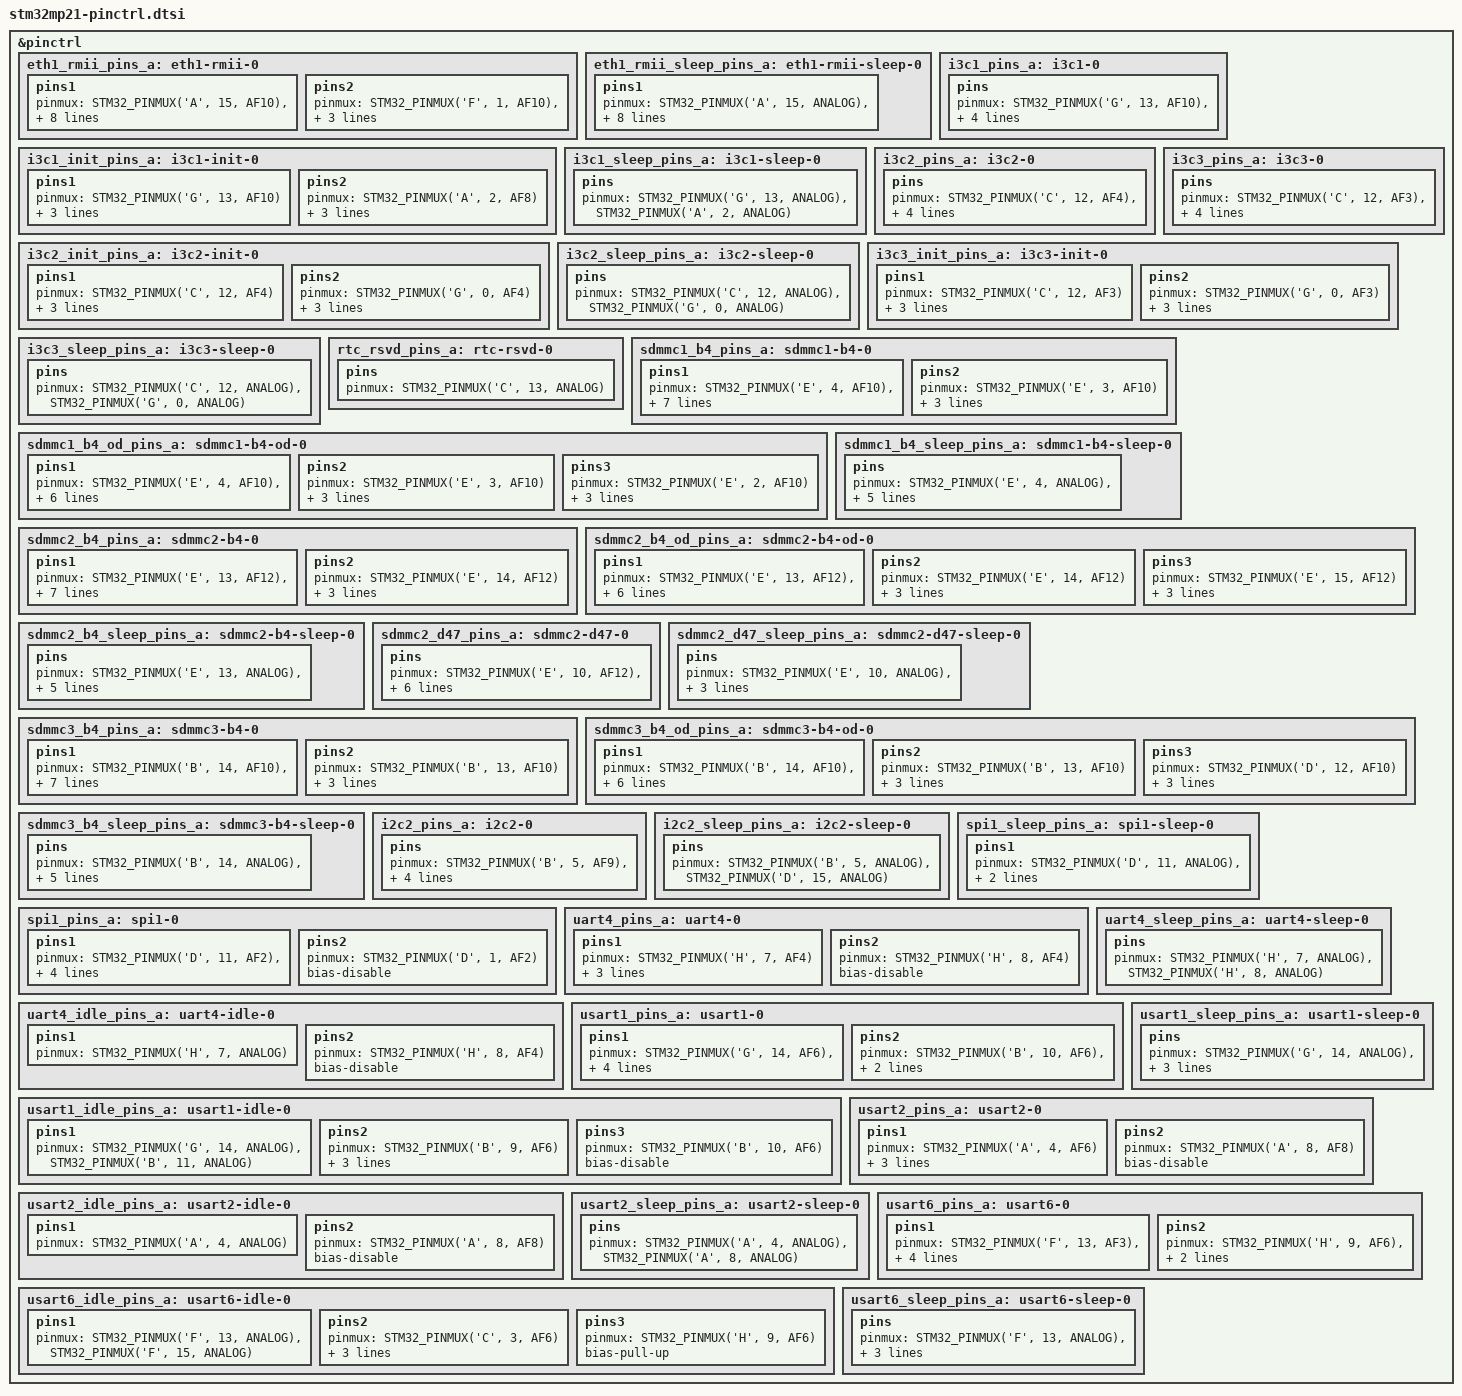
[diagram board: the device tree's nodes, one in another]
// SPDX-License-Identifier: (GPL-2.0-only OR BSD-3-Clause)
/*
 * Copyright (C) 2024-2025, STMicroelectronics - All Rights Reserved
 * Author: Amelie Delaunay <amelie.delaunay@foss.st.com> for STMicroelectronics.
 */
#include <dt-bindings/pinctrl/stm32-pinfunc.h>

&pinctrl {
	/omit-if-no-ref/
	eth1_rmii_pins_a: eth1-rmii-0 {
		pins1 {
			pinmux = <STM32_PINMUX('A', 15, AF10)>, /* ETH_RMII_TXD0 */
				 <STM32_PINMUX('C', 1, AF10)>, /* ETH_RMII_TXD1 */
				 <STM32_PINMUX('A', 13, AF10)>, /* ETH_RMII_TX_EN */
				 <STM32_PINMUX('F', 8, AF9)>, /* ETH_RMII_ETHCK */
				 <STM32_PINMUX('F', 2, AF10)>, /* ETH_MDIO */
				 <STM32_PINMUX('F', 0, AF10)>; /* ETH_MDC */
			bias-disable;
			drive-push-pull;
			slew-rate = <1>;
		};

		pins2 {
			pinmux = <STM32_PINMUX('F', 1, AF10)>, /* ETH_RMII_RXD0 */
				 <STM32_PINMUX('C', 2, AF10)>, /* ETH_RMII_RXD1 */
				 <STM32_PINMUX('A', 11, AF10)>; /* ETH_RMII_CRS_DV */
			bias-disable;
		};

	};

	/omit-if-no-ref/
	eth1_rmii_sleep_pins_a: eth1-rmii-sleep-0 {
		pins1 {
			pinmux = <STM32_PINMUX('A', 15, ANALOG)>, /* ETH_RMII_TXD0 */
				 <STM32_PINMUX('C', 1, ANALOG)>, /* ETH_RMII_TXD1 */
				 <STM32_PINMUX('A', 13, ANALOG)>, /* ETH_RMII_TX_EN */
				 <STM32_PINMUX('F', 8, ANALOG)>, /* ETH_RMII_ETHCK */
				 <STM32_PINMUX('F', 2, ANALOG)>, /* ETH_MDIO */
				 <STM32_PINMUX('F', 0, ANALOG)>, /* ETH_MDC */
				 <STM32_PINMUX('F', 1, ANALOG)>, /* ETH_RMII_RXD0 */
				 <STM32_PINMUX('C', 2, ANALOG)>, /* ETH_RMII_RXD1 */
				 <STM32_PINMUX('A', 11, ANALOG)>; /* ETH_RMII_CRS_DV */
		};
	};

	/omit-if-no-ref/
	i3c1_pins_a: i3c1-0 {
		pins {
			pinmux = <STM32_PINMUX('G', 13, AF10)>, /* I3C1_SCL */
				 <STM32_PINMUX('A', 2, AF8)>; /* I3C1_SDA */
			drive-push-pull;
			bias-disable;
			slew-rate = <3>;
		};
	};

	/omit-if-no-ref/
	i3c1_init_pins_a: i3c1-init-0 {
		pins1 {
			pinmux = <STM32_PINMUX('G', 13, AF10)>; /* I3C1_SCL */
			drive-push-pull;
			bias-disable;
			slew-rate = <1>;
		};
		pins2 {
			pinmux = <STM32_PINMUX('A', 2, AF8)>; /* I3C1_SDA */
			drive-push-pull;
			bias-pull-up;
			slew-rate = <1>;
		};
	};

	/omit-if-no-ref/
	i3c1_sleep_pins_a: i3c1-sleep-0 {
		pins {
			pinmux = <STM32_PINMUX('G', 13, ANALOG)>, /* I3C1_SCL */
				 <STM32_PINMUX('A', 2, ANALOG)>; /* I3C1_SDA */
		};
	};

	/omit-if-no-ref/
	i3c2_pins_a: i3c2-0 {
		pins {
			pinmux = <STM32_PINMUX('C', 12, AF4)>, /* I3C2_SCL */
				 <STM32_PINMUX('G', 0, AF4)>; /* I3C2_SDA */
			drive-push-pull;
			bias-disable;
			slew-rate = <3>;
		};
	};

	/omit-if-no-ref/
	i3c2_init_pins_a: i3c2-init-0 {
		pins1 {
			pinmux = <STM32_PINMUX('C', 12, AF4)>; /* I3C2_SCL */
			drive-push-pull;
			bias-disable;
			slew-rate = <3>;
		};
		pins2 {
			pinmux = <STM32_PINMUX('G', 0, AF4)>; /* I3C2_SDA */
			drive-push-pull;
			bias-pull-up;
			slew-rate = <3>;
		};
	};

	/omit-if-no-ref/
	i3c2_sleep_pins_a: i3c2-sleep-0 {
		pins {
			pinmux = <STM32_PINMUX('C', 12, ANALOG)>, /* I3C2_SCL */
				 <STM32_PINMUX('G', 0, ANALOG)>; /* I3C2_SDA */
		};
	};

	/omit-if-no-ref/
	i3c3_pins_a: i3c3-0 {
		pins {
			pinmux = <STM32_PINMUX('C', 12, AF3)>, /* I3C3_SCL */
				 <STM32_PINMUX('G', 0, AF3)>; /* I3C3_SDA */
			drive-push-pull;
			bias-disable;
			slew-rate = <3>;
		};
	};

	/omit-if-no-ref/
	i3c3_init_pins_a: i3c3-init-0 {
		pins1 {
			pinmux = <STM32_PINMUX('C', 12, AF3)>; /* I3C3_SCL */
			drive-push-pull;
			bias-disable;
			slew-rate = <3>;
		};
		pins2 {
			pinmux = <STM32_PINMUX('G', 0, AF3)>; /* I3C3_SDA */
			drive-push-pull;
			bias-pull-up;
			slew-rate = <3>;
		};
	};

	/omit-if-no-ref/
	i3c3_sleep_pins_a: i3c3-sleep-0 {
		pins {
			pinmux = <STM32_PINMUX('C', 12, ANALOG)>, /* I3C3_SCL */
				 <STM32_PINMUX('G', 0, ANALOG)>; /* I3C3_SDA */
		};
	};

	/omit-if-no-ref/
	rtc_rsvd_pins_a: rtc-rsvd-0 {
		pins {
			pinmux = <STM32_PINMUX('C', 13, ANALOG)>; /* RTC_OUT1 */
		};
	};

	/omit-if-no-ref/
	sdmmc1_b4_pins_a: sdmmc1-b4-0 {
		pins1 {
			pinmux = <STM32_PINMUX('E', 4, AF10)>, /* SDMMC1_D0 */
				 <STM32_PINMUX('E', 5, AF10)>, /* SDMMC1_D1 */
				 <STM32_PINMUX('E', 0, AF10)>, /* SDMMC1_D2 */
				 <STM32_PINMUX('E', 1, AF10)>, /* SDMMC1_D3 */
				 <STM32_PINMUX('E', 2, AF10)>; /* SDMMC1_CMD */
			slew-rate = <2>;
			drive-push-pull;
			bias-disable;
		};
		pins2 {
			pinmux = <STM32_PINMUX('E', 3, AF10)>; /* SDMMC1_CK */
			slew-rate = <3>;
			drive-push-pull;
			bias-disable;
		};
	};

	/omit-if-no-ref/
	sdmmc1_b4_od_pins_a: sdmmc1-b4-od-0 {
		pins1 {
			pinmux = <STM32_PINMUX('E', 4, AF10)>, /* SDMMC1_D0 */
				 <STM32_PINMUX('E', 5, AF10)>, /* SDMMC1_D1 */
				 <STM32_PINMUX('E', 0, AF10)>, /* SDMMC1_D2 */
				 <STM32_PINMUX('E', 1, AF10)>; /* SDMMC1_D3 */
			slew-rate = <2>;
			drive-push-pull;
			bias-disable;
		};
		pins2 {
			pinmux = <STM32_PINMUX('E', 3, AF10)>; /* SDMMC1_CK */
			slew-rate = <3>;
			drive-push-pull;
			bias-disable;
		};
		pins3 {
			pinmux = <STM32_PINMUX('E', 2, AF10)>; /* SDMMC1_CMD */
			slew-rate = <2>;
			drive-open-drain;
			bias-disable;
		};
	};

	/omit-if-no-ref/
	sdmmc1_b4_sleep_pins_a: sdmmc1-b4-sleep-0 {
		pins {
			pinmux = <STM32_PINMUX('E', 4, ANALOG)>, /* SDMMC1_D0 */
				 <STM32_PINMUX('E', 5, ANALOG)>, /* SDMMC1_D1 */
				 <STM32_PINMUX('E', 0, ANALOG)>, /* SDMMC1_D2 */
				 <STM32_PINMUX('E', 1, ANALOG)>, /* SDMMC1_D3 */
				 <STM32_PINMUX('E', 3, ANALOG)>, /* SDMMC1_CK */
				 <STM32_PINMUX('E', 2, ANALOG)>; /* SDMMC1_CMD */
		};
	};

	/omit-if-no-ref/
	sdmmc2_b4_pins_a: sdmmc2-b4-0 {
		pins1 {
			pinmux = <STM32_PINMUX('E', 13, AF12)>, /* SDMMC2_D0 */
				 <STM32_PINMUX('E', 11, AF12)>, /* SDMMC2_D1 */
				 <STM32_PINMUX('E', 8, AF12)>, /* SDMMC2_D2 */
				 <STM32_PINMUX('E', 12, AF12)>, /* SDMMC2_D3 */
				 <STM32_PINMUX('E', 15, AF12)>; /* SDMMC2_CMD */
			slew-rate = <2>;
			drive-push-pull;
			bias-pull-up;
		};
		pins2 {
			pinmux = <STM32_PINMUX('E', 14, AF12)>; /* SDMMC2_CK */
			slew-rate = <3>;
			drive-push-pull;
			bias-pull-up;
		};
	};

	/omit-if-no-ref/
	sdmmc2_b4_od_pins_a: sdmmc2-b4-od-0 {
		pins1 {
			pinmux = <STM32_PINMUX('E', 13, AF12)>, /* SDMMC2_D0 */
				 <STM32_PINMUX('E', 11, AF12)>, /* SDMMC2_D1 */
				 <STM32_PINMUX('E', 8, AF12)>, /* SDMMC2_D2 */
				 <STM32_PINMUX('E', 12, AF12)>; /* SDMMC2_D3 */
			slew-rate = <2>;
			drive-push-pull;
			bias-pull-up;
		};
		pins2 {
			pinmux = <STM32_PINMUX('E', 14, AF12)>; /* SDMMC2_CK */
			slew-rate = <3>;
			drive-push-pull;
			bias-pull-up;
		};
		pins3 {
			pinmux = <STM32_PINMUX('E', 15, AF12)>; /* SDMMC2_CMD */
			slew-rate = <2>;
			drive-open-drain;
			bias-pull-up;
		};
	};

	/omit-if-no-ref/
	sdmmc2_b4_sleep_pins_a: sdmmc2-b4-sleep-0 {
		pins {
			pinmux = <STM32_PINMUX('E', 13, ANALOG)>, /* SDMMC2_D0 */
				 <STM32_PINMUX('E', 11, ANALOG)>, /* SDMMC2_D1 */
				 <STM32_PINMUX('E', 8, ANALOG)>, /* SDMMC2_D2 */
				 <STM32_PINMUX('E', 12, ANALOG)>, /* SDMMC2_D3 */
				 <STM32_PINMUX('E', 14, ANALOG)>, /* SDMMC2_CK */
				 <STM32_PINMUX('E', 15, ANALOG)>; /* SDMMC2_CMD */
		};
	};

	/omit-if-no-ref/
	sdmmc2_d47_pins_a: sdmmc2-d47-0 {
		pins {
			pinmux = <STM32_PINMUX('E', 10, AF12)>, /* SDMMC2_D4 */
				 <STM32_PINMUX('E', 9, AF12)>, /* SDMMC2_D5 */
				 <STM32_PINMUX('E', 6, AF12)>, /* SDMMC2_D6 */
				 <STM32_PINMUX('E', 7, AF12)>; /* SDMMC2_D7 */
			slew-rate = <2>;
			drive-push-pull;
			bias-pull-up;
		};
	};

	/omit-if-no-ref/
	sdmmc2_d47_sleep_pins_a: sdmmc2-d47-sleep-0 {
		pins {
			pinmux = <STM32_PINMUX('E', 10, ANALOG)>, /* SDMMC2_D4 */
				 <STM32_PINMUX('E', 9, ANALOG)>, /* SDMMC2_D5 */
				 <STM32_PINMUX('E', 6, ANALOG)>, /* SDMMC2_D6 */
				 <STM32_PINMUX('E', 7, ANALOG)>; /* SDMMC2_D7 */
		};
	};

	/omit-if-no-ref/
	sdmmc3_b4_pins_a: sdmmc3-b4-0 {
		pins1 {
			pinmux = <STM32_PINMUX('B', 14, AF10)>, /* SDMMC3_D0 */
				 <STM32_PINMUX('D', 13, AF10)>, /* SDMMC3_D1 */
				 <STM32_PINMUX('B', 12, AF10)>, /* SDMMC3_D2 */
				 <STM32_PINMUX('D', 14, AF12)>, /* SDMMC3_D3 */
				 <STM32_PINMUX('D', 12, AF10)>; /* SDMMC3_CMD */
			slew-rate = <2>;
			drive-push-pull;
			bias-pull-up;
		};
		pins2 {
			pinmux = <STM32_PINMUX('B', 13, AF10)>; /* SDMMC3_CK */
			slew-rate = <3>;
			drive-push-pull;
			bias-pull-up;
		};
	};

	/omit-if-no-ref/
	sdmmc3_b4_od_pins_a: sdmmc3-b4-od-0 {
		pins1 {
			pinmux = <STM32_PINMUX('B', 14, AF10)>, /* SDMMC3_D0 */
				 <STM32_PINMUX('D', 13, AF10)>, /* SDMMC3_D1 */
				 <STM32_PINMUX('B', 12, AF10)>, /* SDMMC3_D2 */
				 <STM32_PINMUX('D', 14, AF12)>; /* SDMMC3_D3 */
			slew-rate = <2>;
			drive-push-pull;
			bias-pull-up;
		};
		pins2 {
			pinmux = <STM32_PINMUX('B', 13, AF10)>; /* SDMMC3_CK */
			slew-rate = <3>;
			drive-push-pull;
			bias-pull-up;
		};
		pins3 {
			pinmux = <STM32_PINMUX('D', 12, AF10)>; /* SDMMC3_CMD */
			slew-rate = <2>;
			drive-open-drain;
			bias-pull-up;
		};
	};

	/omit-if-no-ref/
	sdmmc3_b4_sleep_pins_a: sdmmc3-b4-sleep-0 {
		pins {
			pinmux = <STM32_PINMUX('B', 14, ANALOG)>, /* SDMMC1_D0 */
				 <STM32_PINMUX('D', 13, ANALOG)>, /* SDMMC1_D1 */
				 <STM32_PINMUX('B', 12, ANALOG)>, /* SDMMC1_D2 */
				 <STM32_PINMUX('D', 14, ANALOG)>, /* SDMMC1_D3 */
				 <STM32_PINMUX('B', 13, ANALOG)>, /* SDMMC1_CK */
				 <STM32_PINMUX('D', 12, ANALOG)>; /* SDMMC1_CMD */
		};
	};

	/omit-if-no-ref/
	i2c2_pins_a: i2c2-0 {
		pins {
			pinmux = <STM32_PINMUX('B', 5, AF9)>, /* I2C2_SCL */
				 <STM32_PINMUX('D', 15, AF6)>; /* I2C2_SDA */
			bias-disable;
			drive-open-drain;
			slew-rate = <0>;
		};
	};

	/omit-if-no-ref/
	i2c2_sleep_pins_a: i2c2-sleep-0 {
		pins {
			pinmux = <STM32_PINMUX('B', 5, ANALOG)>, /* I2C2_SCL */
				 <STM32_PINMUX('D', 15, ANALOG)>; /* I2C2_SDA */
		};
	};

	/omit-if-no-ref/
	spi1_pins_a: spi1-0 {
		pins1 {
			pinmux = <STM32_PINMUX('D', 11, AF2)>, /* SPI1_SCK */
				 <STM32_PINMUX('I', 5, AF3)>; /* SPI1_MOSI */
			drive-push-pull;
			bias-disable;
			slew-rate = <1>;
		};
		pins2 {
			pinmux = <STM32_PINMUX('D', 1, AF2)>; /* SPI1_MISO */
			bias-disable;
		};
	};

	/omit-if-no-ref/
	spi1_sleep_pins_a: spi1-sleep-0 {
		pins1 {
			pinmux = <STM32_PINMUX('D', 11, ANALOG)>, /* SPI1_SCK */
				 <STM32_PINMUX('I', 5, ANALOG)>, /* SPI1_MOSI */
				 <STM32_PINMUX('D', 1, ANALOG)>; /* SPI1_MISO */
		};
	};

	/omit-if-no-ref/
	uart4_pins_a: uart4-0 {
		pins1 {
			pinmux = <STM32_PINMUX('H', 7, AF4)>; /* UART4_TX */
			bias-disable;
			drive-push-pull;
			slew-rate = <0>;
		};
		pins2 {
			pinmux = <STM32_PINMUX('H', 8, AF4)>; /* UART4_RX */
			bias-disable;
		};
	};

	/omit-if-no-ref/
	uart4_idle_pins_a: uart4-idle-0 {
		pins1 {
			pinmux = <STM32_PINMUX('H', 7, ANALOG)>; /* UART4_TX */
		};
		pins2 {
			pinmux = <STM32_PINMUX('H', 8, AF4)>; /* UART4_RX */
			bias-disable;
		};
	};

	/omit-if-no-ref/
	uart4_sleep_pins_a: uart4-sleep-0 {
		pins {
			pinmux = <STM32_PINMUX('H', 7, ANALOG)>, /* UART4_TX */
				 <STM32_PINMUX('H', 8, ANALOG)>; /* UART4_RX */
		};
	};

	/omit-if-no-ref/
	usart1_pins_a: usart1-0 {
		pins1 {
			pinmux = <STM32_PINMUX('G', 14, AF6)>, /* USART1_TX */
				 <STM32_PINMUX('B', 9, AF6)>; /* USART1_RTS */
			bias-disable;
			drive-push-pull;
			slew-rate = <0>;
		};
		pins2 {
			pinmux = <STM32_PINMUX('B', 10, AF6)>, /* USART1_RX */
				 <STM32_PINMUX('B', 11, AF6)>; /* USART1_CTS_NSS */
			bias-disable;
		};
	};

	/omit-if-no-ref/
	usart1_idle_pins_a: usart1-idle-0 {
		pins1 {
			pinmux = <STM32_PINMUX('G', 14, ANALOG)>, /* USART1_TX */
				 <STM32_PINMUX('B', 11, ANALOG)>; /* USART1_CTS_NSS */
		};
		pins2 {
			pinmux = <STM32_PINMUX('B', 9, AF6)>; /* USART1_RTS */
			bias-disable;
			drive-push-pull;
			slew-rate = <0>;
		};
		pins3 {
			pinmux = <STM32_PINMUX('B', 10, AF6)>; /* USART1_RX */
			bias-disable;
		};
	};

	/omit-if-no-ref/
	usart1_sleep_pins_a: usart1-sleep-0 {
		pins {
			pinmux = <STM32_PINMUX('G', 14, ANALOG)>, /* USART1_TX */
				 <STM32_PINMUX('B', 11, ANALOG)>, /* USART1_RTS */
				 <STM32_PINMUX('B', 9, ANALOG)>, /* USART1_CTS_NSS */
				 <STM32_PINMUX('B', 10, ANALOG)>; /* USART1_RX */
		};
	};

	/omit-if-no-ref/
	usart2_pins_a: usart2-0 {
		pins1 {
			pinmux = <STM32_PINMUX('A', 4, AF6)>; /* USART2_TX */
			bias-disable;
			drive-push-pull;
			slew-rate = <0>;
		};
		pins2 {
			pinmux = <STM32_PINMUX('A', 8, AF8)>; /* USART2_RX */
			bias-disable;
		};
	};

	/omit-if-no-ref/
	usart2_idle_pins_a: usart2-idle-0 {
		pins1 {
			pinmux = <STM32_PINMUX('A', 4, ANALOG)>; /* USART2_TX */
		};
		pins2 {
			pinmux = <STM32_PINMUX('A', 8, AF8)>; /* USART2_RX */
			bias-disable;
		};
	};

	/omit-if-no-ref/
	usart2_sleep_pins_a: usart2-sleep-0 {
		pins {
			pinmux = <STM32_PINMUX('A', 4, ANALOG)>, /* USART2_TX */
				 <STM32_PINMUX('A', 8, ANALOG)>; /* USART2_RX */
		};
	};

	/omit-if-no-ref/
	usart6_pins_a: usart6-0 {
		pins1 {
			pinmux = <STM32_PINMUX('F', 13, AF3)>, /* USART6_TX */
				 <STM32_PINMUX('C', 3, AF6)>;  /* USART6_RTS */
			bias-disable;
			drive-push-pull;
			slew-rate = <0>;
		};
		pins2 {
			pinmux = <STM32_PINMUX('H', 9, AF6)>, /* USART6_RX */
				 <STM32_PINMUX('F', 15, AF3)>; /* USART6_CTS_NSS */
			bias-pull-up;
		};
	};

	/omit-if-no-ref/
	usart6_idle_pins_a: usart6-idle-0 {
		pins1 {
			pinmux = <STM32_PINMUX('F', 13, ANALOG)>, /* USART6_TX */
				 <STM32_PINMUX('F', 15, ANALOG)>; /* USART6_CTS_NSS */
		};
		pins2 {
			pinmux = <STM32_PINMUX('C', 3, AF6)>; /* USART6_RTS */
			bias-disable;
			drive-push-pull;
			slew-rate = <0>;
		};
		pins3 {
			pinmux = <STM32_PINMUX('H', 9, AF6)>; /* USART6_RX */
			bias-pull-up;
		};
	};

	/omit-if-no-ref/
	usart6_sleep_pins_a: usart6-sleep-0 {
		pins {
			pinmux = <STM32_PINMUX('F', 13, ANALOG)>, /* USART6_TX */
				 <STM32_PINMUX('C', 3, ANALOG)>,  /* USART6_RTS */
				 <STM32_PINMUX('F', 15, ANALOG)>, /* USART6_CTS_NSS */
				 <STM32_PINMUX('H', 9, ANALOG)>; /* USART6_RX */
		};
	};
};
